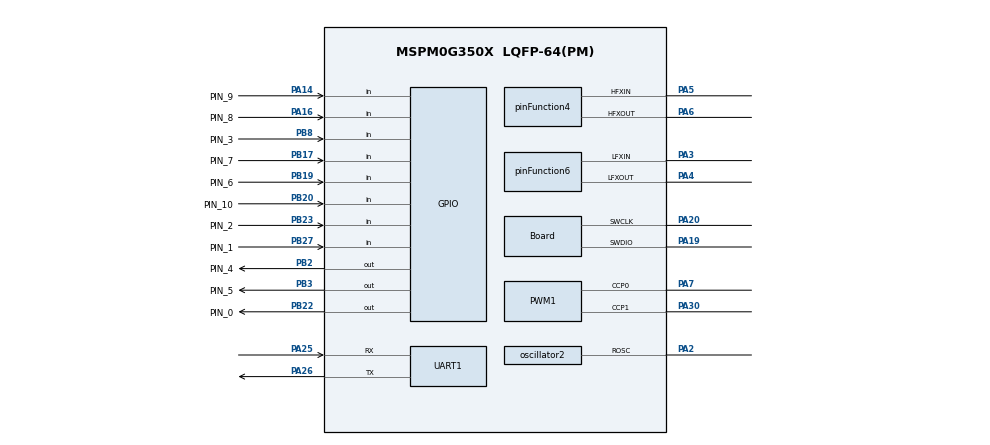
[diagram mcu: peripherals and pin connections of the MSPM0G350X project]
/**
 *
 * @cliArgs --device "MSPM0G350X" --part "Default" --package "LQFP-64(PM)" --product "mspm0_sdk@2.11.00.07"
 * @versions {"tool":"1.28.0+4712"}
 */

/**
 * Import the modules used in this configuration.
 */
const GPIO          = scripting.addModule("/ti/driverlib/GPIO", {}, false);
const GPIO1         = GPIO.addInstance();
const GPIO2         = GPIO.addInstance();
const GPIO3         = GPIO.addInstance();
const GPIO4         = GPIO.addInstance();
const GPIO5         = GPIO.addInstance();
const GPIO6         = GPIO.addInstance();
const GPIO7         = GPIO.addInstance();
const GPIO8         = GPIO.addInstance();
const GPIO9         = GPIO.addInstance();
const GPIO10        = GPIO.addInstance();
const GPIO11        = GPIO.addInstance();
const GPIO12        = GPIO.addInstance();
const GPIO13        = GPIO.addInstance();
const GPIO14        = GPIO.addInstance();
const GPIO15        = GPIO.addInstance();
const GPIO16        = GPIO.addInstance();
const GPIO17        = GPIO.addInstance();
const GPIO18        = GPIO.addInstance();
const GPIO19        = GPIO.addInstance();
const GPIO20        = GPIO.addInstance();
const GPIO21        = GPIO.addInstance();
const GPIO22        = GPIO.addInstance();
const GPIO23        = GPIO.addInstance();
const GPIO24        = GPIO.addInstance();
const PWM           = scripting.addModule("/ti/driverlib/PWM", {}, false);
const PWM1          = PWM.addInstance();
const RTC           = scripting.addModule("/ti/driverlib/RTC");
const SYSCTL        = scripting.addModule("/ti/driverlib/SYSCTL");
const TIMER         = scripting.addModule("/ti/driverlib/TIMER", {}, false);
const TIMER1        = TIMER.addInstance();
const UART          = scripting.addModule("/ti/driverlib/UART", {}, false);
const UART1         = UART.addInstance();
const ProjectConfig = scripting.addModule("/ti/project_config/ProjectConfig");

/**
 * Write custom configuration values to the imported modules.
 */
const divider9       = system.clockTree["UDIV"];
divider9.divideValue = 2;

const gate7  = system.clockTree["MFCLKGATE"];
gate7.enable = true;

const gate8  = system.clockTree["MFPCLKGATE"];
gate8.enable = true;

const multiplier2         = system.clockTree["PLL_QDIV"];
multiplier2.multiplyValue = 4;

const mux4       = system.clockTree["EXHFMUX"];
mux4.inputSelect = "EXHFMUX_XTAL";

const mux5       = system.clockTree["EXLFMUX"];
mux5.inputSelect = "EXLFMUX_XTAL";

const mux8       = system.clockTree["HSCLKMUX"];
mux8.inputSelect = "HSCLKMUX_SYSPLL0";

const mux12       = system.clockTree["SYSPLLMUX"];
mux12.inputSelect = "zSYSPLLMUX_HFCLK";

const oscillator2                      = system.clockTree["SYSOSC"];
oscillator2.enableSYSOSCFCL            = true;
oscillator2.enableROSC                 = true;
oscillator2.peripheral.$assign         = "SYSCTL";
oscillator2.peripheral.roscPin.$assign = "PA2";

const pinFunction4                        = system.clockTree["HFXT"];
pinFunction4.inputFreq                    = 40;
pinFunction4.enable                       = true;
pinFunction4.HFXTStartup                  = 10;
pinFunction4.peripheral.$assign           = "SYSCTL";
pinFunction4.peripheral.hfxInPin.$assign  = "PA5";
pinFunction4.peripheral.hfxOutPin.$assign = "PA6";

const pinFunction6                        = system.clockTree["LFXT"];
pinFunction6.enable                       = true;
pinFunction6.inputFreq                    = 32.768;
pinFunction6.peripheral.$assign           = "SYSCTL";
pinFunction6.peripheral.lfxInPin.$assign  = "PA3";
pinFunction6.peripheral.lfxOutPin.$assign = "PA4";

GPIO1.$name                         = "GPIO_GRP_22";
GPIO1.port                          = "PORTB";
GPIO1.associatedPins[0].$name       = "PIN_0";
GPIO1.associatedPins[0].assignedPin = "22";
GPIO1.associatedPins[0].ioStructure = "SD";
GPIO1.associatedPins[0].pin.$assign = "PB22";

const Board                       = scripting.addModule("/ti/driverlib/Board", {}, false);
Board.peripheral.$assign          = "DEBUGSS";
Board.peripheral.swclkPin.$assign = "PA20";
Board.peripheral.swdioPin.$assign = "PA19";

GPIO2.$name                              = "key1";
GPIO2.port                               = "PORTB";
GPIO2.associatedPins[0].$name            = "PIN_1";
GPIO2.associatedPins[0].assignedPin      = "27";
GPIO2.associatedPins[0].direction        = "INPUT";
GPIO2.associatedPins[0].internalResistor = "PULL_UP";
GPIO2.associatedPins[0].pin.$assign      = "PB27";

GPIO3.$name                              = "key2";
GPIO3.port                               = "PORTB";
GPIO3.associatedPins[0].$name            = "PIN_2";
GPIO3.associatedPins[0].assignedPin      = "23";
GPIO3.associatedPins[0].direction        = "INPUT";
GPIO3.associatedPins[0].internalResistor = "PULL_UP";
GPIO3.associatedPins[0].pin.$assign      = "PB23";

GPIO4.$name                              = "key3";
GPIO4.port                               = "PORTB";
GPIO4.associatedPins[0].$name            = "PIN_3";
GPIO4.associatedPins[0].assignedPin      = "8";
GPIO4.associatedPins[0].direction        = "INPUT";
GPIO4.associatedPins[0].internalResistor = "PULL_UP";
GPIO4.associatedPins[0].pin.$assign      = "PB8";

GPIO5.$name                          = "OLED_SCL";
GPIO5.port                           = "PORTB";
GPIO5.associatedPins[0].$name        = "PIN_4";
GPIO5.associatedPins[0].assignedPin  = "2";
GPIO5.associatedPins[0].hiZ          = "ENABLE";
GPIO5.associatedPins[0].initialValue = "SET";
GPIO5.associatedPins[0].pin.$assign  = "PB2";

GPIO6.$name                          = "OLED_SDA";
GPIO6.port                           = "PORTB";
GPIO6.associatedPins[0].$name        = "PIN_5";
GPIO6.associatedPins[0].assignedPin  = "3";
GPIO6.associatedPins[0].initialValue = "SET";
GPIO6.associatedPins[0].hiZ          = "ENABLE";
GPIO6.associatedPins[0].pin.$assign  = "PB3";

GPIO7.port                               = "PORTB";
GPIO7.$name                              = "GraySensor_L4";
GPIO7.associatedPins[0].$name            = "PIN_6";
GPIO7.associatedPins[0].assignedPin      = "19";
GPIO7.associatedPins[0].direction        = "INPUT";
GPIO7.associatedPins[0].internalResistor = "PULL_UP";
GPIO7.associatedPins[0].pin.$assign      = "PB19";

GPIO8.port                               = "PORTB";
GPIO8.$name                              = "GraySensor_L3";
GPIO8.associatedPins[0].$name            = "PIN_7";
GPIO8.associatedPins[0].assignedPin      = "17";
GPIO8.associatedPins[0].direction        = "INPUT";
GPIO8.associatedPins[0].internalResistor = "PULL_UP";
GPIO8.associatedPins[0].pin.$assign      = "PB17";

GPIO9.port                               = "PORTA";
GPIO9.$name                              = "GraySensor_L2";
GPIO9.associatedPins[0].$name            = "PIN_8";
GPIO9.associatedPins[0].assignedPin      = "16";
GPIO9.associatedPins[0].direction        = "INPUT";
GPIO9.associatedPins[0].internalResistor = "PULL_UP";
GPIO9.associatedPins[0].pin.$assign      = "PA16";

GPIO10.port                               = "PORTA";
GPIO10.$name                              = "GraySensor_L1";
GPIO10.associatedPins[0].$name            = "PIN_9";
GPIO10.associatedPins[0].assignedPin      = "14";
GPIO10.associatedPins[0].direction        = "INPUT";
GPIO10.associatedPins[0].internalResistor = "PULL_UP";
GPIO10.associatedPins[0].pin.$assign      = "PA14";

GPIO11.port                               = "PORTB";
GPIO11.$name                              = "GraySensor_R1";
GPIO11.associatedPins[0].$name            = "PIN_10";
GPIO11.associatedPins[0].assignedPin      = "20";
GPIO11.associatedPins[0].direction        = "INPUT";
GPIO11.associatedPins[0].internalResistor = "PULL_UP";
GPIO11.associatedPins[0].pin.$assign      = "PB20";

GPIO12.$name                         = "M1";
GPIO12.port                          = "PORTB";
GPIO12.associatedPins[0].$name       = "PIN_11";
GPIO12.associatedPins[0].assignedPin = "10";
GPIO12.associatedPins[0].ioStructure = "SD";

GPIO13.$name                         = "M_1";
GPIO13.port                          = "PORTB";
GPIO13.associatedPins[0].$name       = "PIN_12";
GPIO13.associatedPins[0].assignedPin = "9";
GPIO13.associatedPins[0].ioStructure = "SD";

GPIO14.$name                         = "M2";
GPIO14.port                          = "PORTB";
GPIO14.associatedPins[0].$name       = "PIN_13";
GPIO14.associatedPins[0].assignedPin = "7";
GPIO14.associatedPins[0].ioStructure = "SD";

GPIO15.$name                         = "M_2";
GPIO15.port                          = "PORTB";
GPIO15.associatedPins[0].$name       = "PIN_14";
GPIO15.associatedPins[0].ioStructure = "SD";
GPIO15.associatedPins[0].assignedPin = "6";

GPIO16.$name                          = "LED1";
GPIO16.port                           = "PORTA";
GPIO16.associatedPins[0].$name        = "PIN_15";
GPIO16.associatedPins[0].assignedPin  = "29";
GPIO16.associatedPins[0].initialValue = "SET";

GPIO17.$name                          = "LED2";
GPIO17.port                           = "PORTB";
GPIO17.associatedPins[0].$name        = "PIN_16";
GPIO17.associatedPins[0].assignedPin  = "26";
GPIO17.associatedPins[0].initialValue = "SET";

GPIO18.port                               = "PORTB";
GPIO18.$name                              = "GraySensor_R4";
GPIO18.associatedPins[0].$name            = "PIN_17";
GPIO18.associatedPins[0].assignedPin      = "0";
GPIO18.associatedPins[0].initialValue     = "SET";
GPIO18.associatedPins[0].direction        = "INPUT";
GPIO18.associatedPins[0].internalResistor = "PULL_UP";

GPIO19.port                                = "PORTB";
GPIO19.$name                               = "Motor2A";
GPIO19.associatedPins[0].$name             = "PIN_18";
GPIO19.associatedPins[0].assignedPin       = "4";
GPIO19.associatedPins[0].direction         = "INPUT";
GPIO19.associatedPins[0].interruptEn       = true;
GPIO19.associatedPins[0].interruptPriority = "1";
GPIO19.associatedPins[0].polarity          = "RISE";
GPIO19.associatedPins[0].internalResistor  = "PULL_UP";

GPIO20.port                                = "PORTB";
GPIO20.$name                               = "Motor2B";
GPIO20.associatedPins[0].$name             = "PIN_19";
GPIO20.associatedPins[0].assignedPin       = "5";
GPIO20.associatedPins[0].direction         = "INPUT";
GPIO20.associatedPins[0].interruptEn       = true;
GPIO20.associatedPins[0].polarity          = "RISE";
GPIO20.associatedPins[0].interruptPriority = "1";
GPIO20.associatedPins[0].internalResistor  = "PULL_UP";

GPIO21.$name                               = "Motor1A";
GPIO21.port                                = "PORTB";
GPIO21.associatedPins[0].$name             = "PIN_20";
GPIO21.associatedPins[0].direction         = "INPUT";
GPIO21.associatedPins[0].assignedPin       = "12";
GPIO21.associatedPins[0].interruptEn       = true;
GPIO21.associatedPins[0].interruptPriority = "1";
GPIO21.associatedPins[0].polarity          = "RISE";
GPIO21.associatedPins[0].internalResistor  = "PULL_UP";

GPIO22.$name                               = "Motor1B";
GPIO22.port                                = "PORTB";
GPIO22.associatedPins[0].$name             = "PIN_21";
GPIO22.associatedPins[0].direction         = "INPUT";
GPIO22.associatedPins[0].interruptEn       = true;
GPIO22.associatedPins[0].polarity          = "RISE";
GPIO22.associatedPins[0].interruptPriority = "1";
GPIO22.associatedPins[0].internalResistor  = "PULL_DOWN";
GPIO22.associatedPins[0].assignedPin       = "13";

GPIO23.$name                              = "GraySensor_R2";
GPIO23.port                               = "PORTB";
GPIO23.associatedPins[0].$name            = "PIN_22";
GPIO23.associatedPins[0].direction        = "INPUT";
GPIO23.associatedPins[0].internalResistor = "PULL_UP";
GPIO23.associatedPins[0].assignedPin      = "25";

GPIO24.$name                              = "GraySensor_R3";
GPIO24.port                               = "PORTA";
GPIO24.associatedPins[0].$name            = "PIN_23";
GPIO24.associatedPins[0].direction        = "INPUT";
GPIO24.associatedPins[0].internalResistor = "PULL_UP";
GPIO24.associatedPins[0].assignedPin      = "27";

PWM1.clockPrescale                      = 20;
PWM1.timerCount                         = 99;
PWM1.timerStartTimer                    = true;
PWM1.pwmMode                            = "EDGE_ALIGN_UP";
PWM1.$name                              = "PWM1";
PWM1.peripheral.$assign                 = "TIMG8";
PWM1.peripheral.ccp0Pin.$assign         = "PA7";
PWM1.peripheral.ccp1Pin.$assign         = "PA30";
PWM1.PWM_CHANNEL_0.$name                = "ti_driverlib_pwm_PWMTimerCC0";
PWM1.PWM_CHANNEL_1.$name                = "ti_driverlib_pwm_PWMTimerCC1";
PWM1.ccp0PinConfig.$name                = "ti_driverlib_gpio_GPIOPinGeneric0";
PWM1.ccp0PinConfig.direction            = scripting.forceWrite("OUTPUT");
PWM1.ccp0PinConfig.hideOutputInversion  = scripting.forceWrite(false);
PWM1.ccp0PinConfig.onlyInternalResistor = scripting.forceWrite(false);
PWM1.ccp0PinConfig.passedPeripheralType = scripting.forceWrite("Digital");
PWM1.ccp0PinConfig.enableConfig         = true;
PWM1.ccp1PinConfig.$name                = "ti_driverlib_gpio_GPIOPinGeneric1";
PWM1.ccp1PinConfig.direction            = scripting.forceWrite("OUTPUT");
PWM1.ccp1PinConfig.hideOutputInversion  = scripting.forceWrite(false);
PWM1.ccp1PinConfig.onlyInternalResistor = scripting.forceWrite(false);
PWM1.ccp1PinConfig.passedPeripheralType = scripting.forceWrite("Digital");
PWM1.ccp1PinConfig.enableConfig         = true;

RTC.peripheral.$assign = "RTC";

SYSCTL.clockTreeEn = true;

TIMER1.$name              = "TIMER_0";
TIMER1.timerMode          = "PERIODIC";
TIMER1.timerPeriod        = "1 ms";
TIMER1.timerStartTimer    = true;
TIMER1.interrupts         = ["ZERO"];
TIMER1.peripheral.$assign = "TIMG0";

UART1.$name                    = "UART_0";
UART1.peripheral.$assign       = "UART3";
UART1.peripheral.rxPin.$assign = "PA25";
UART1.peripheral.txPin.$assign = "PA26";
UART1.txPinConfig.$name        = "ti_driverlib_gpio_GPIOPinGeneric6";
UART1.rxPinConfig.$name        = "ti_driverlib_gpio_GPIOPinGeneric7";

ProjectConfig.migrationCondition = true;

/**
 * Pinmux solution for unlocked pins/peripherals. This ensures that minor changes to the automatic solver in a future
 * version of the tool will not impact the pinmux you originally saw.  These lines can be completely deleted in order to
 * re-solve from scratch.
 */
GPIO12.associatedPins[0].pin.$suggestSolution = "PB10";
GPIO13.associatedPins[0].pin.$suggestSolution = "PB9";
GPIO14.associatedPins[0].pin.$suggestSolution = "PB7";
GPIO15.associatedPins[0].pin.$suggestSolution = "PB6";
GPIO16.associatedPins[0].pin.$suggestSolution = "PA29";
GPIO17.associatedPins[0].pin.$suggestSolution = "PB26";
GPIO18.associatedPins[0].pin.$suggestSolution = "PB0";
GPIO19.associatedPins[0].pin.$suggestSolution = "PB4";
GPIO20.associatedPins[0].pin.$suggestSolution = "PB5";
GPIO21.associatedPins[0].pin.$suggestSolution = "PB12";
GPIO22.associatedPins[0].pin.$suggestSolution = "PB13";
GPIO23.associatedPins[0].pin.$suggestSolution = "PB25";
GPIO24.associatedPins[0].pin.$suggestSolution = "PA27";
